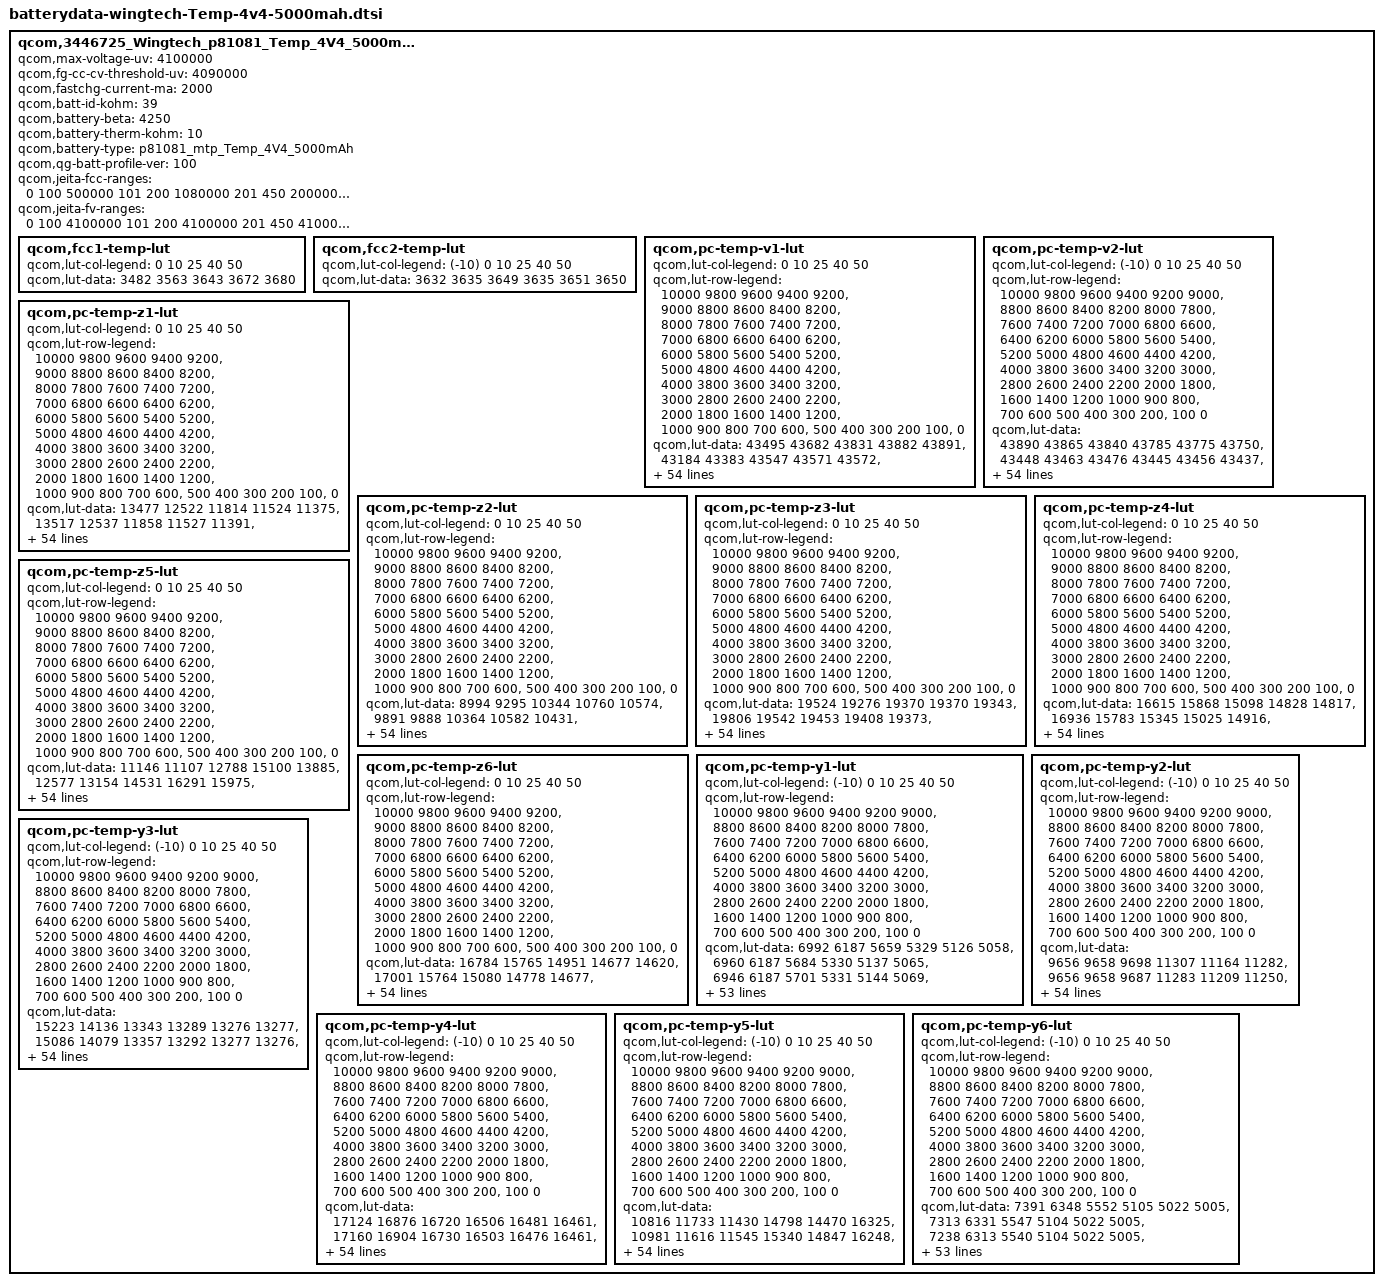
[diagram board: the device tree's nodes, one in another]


qcom,3446725_Wingtech_p81081_Temp_4V4_5000mAh {
	/* 3446725_Wingtech_k81822_Jiade_3600mAh_averaged_MasterSlave_May16th2018 */
	qcom,max-voltage-uv = <4100000>;
	qcom,fg-cc-cv-threshold-uv = <4090000>;
	qcom,fastchg-current-ma = <2000>;
	qcom,batt-id-kohm = <39>;
	qcom,battery-beta = <4250>;
	qcom,battery-therm-kohm = <10>;
	qcom,battery-type = "p81081_mtp_Temp_4V4_5000mAh";
	qcom,qg-batt-profile-ver = <100>;
	/*bug 356255 zhaolinquan.wt 20170522 0-45 degree C charging, other temperatur don't charging*/
	/* COLD = 0 DegC, HOT = 45 DegC */
	//qcom,jeita-hard-thresholds = <0x6894 0xb14>;//bug 357121 zhaolinquan.wt 20170524 0 and 45 degree C stop charging is not accurate
	//+bug 356474 zhaolinquan.wt 20170524 0-45 degree C setting charging current by batt SPEC
	qcom,jeita-fcc-ranges = <0   100  500000
				101  200  1080000
				201  450  2000000
				451  580  1000000>;
	qcom,jeita-fv-ranges = <0   100  4100000
				101 200  4100000
				201 450  4100000
				451 580  4100000>;
	//+bug 356474 zhaolinquan.wt 20170524 0-45 degree C setting charging current by batt SPEC
	qcom,fcc1-temp-lut {
		qcom,lut-col-legend = <0 10 25 40 50>;
		qcom,lut-data = <3482 3563 3643 3672 3680>;
	};

	qcom,fcc2-temp-lut {
		qcom,lut-col-legend = <(-10) 0 10 25 40 50>;
		qcom,lut-data = <3632 3635 3649 3635 3651 3650>;
	};

	qcom,pc-temp-v1-lut {
		qcom,lut-col-legend = <0 10 25 40 50>;
		qcom,lut-row-legend = <10000 9800 9600 9400 9200>,
			<9000 8800 8600 8400 8200>,
			<8000 7800 7600 7400 7200>,
			<7000 6800 6600 6400 6200>,
			<6000 5800 5600 5400 5200>,
			<5000 4800 4600 4400 4200>,
			<4000 3800 3600 3400 3200>,
			<3000 2800 2600 2400 2200>,
			<2000 1800 1600 1400 1200>,
			<1000 900 800 700 600>,
			<500 400 300 200 100>,
			<0>;
		qcom,lut-data = <43495 43682 43831 43882 43891>,
			<43184 43383 43547 43571 43572>,
			<42923 43108 43282 43309 43309>,
			<42685 42857 43027 43064 43062>,
			<42451 42623 42780 42822 42821>,
			<42225 42390 42541 42584 42586>,
			<42005 42159 42304 42349 42355>,
			<41790 41935 42068 42113 42120>,
			<41583 41715 41837 41881 41888>,
			<41387 41503 41611 41653 41661>,
			<41215 41307 41390 41429 41438>,
			<41035 41135 41186 41210 41219>,
			<40804 40952 41001 40994 41003>,
			<40530 40713 40806 40786 40793>,
			<40286 40440 40565 40585 40591>,
			<40082 40218 40321 40391 40397>,
			<39902 40041 40136 40207 40211>,
			<39752 39886 39992 40031 40034>,
			<39627 39749 39850 39862 39863>,
			<39508 39625 39707 39708 39706>,
			<39390 39495 39556 39560 39557>,
			<39275 39356 39360 39375 39378>,
			<39155 39206 39112 39122 39138>,
			<39028 39014 38904 38898 38917>,
			<38907 38791 38746 38755 38769>,
			<38798 38628 38618 38642 38650>,
			<38699 38518 38523 38537 38539>,
			<38609 38433 38450 38440 38435>,
			<38528 38373 38380 38352 38342>,
			<38454 38327 38308 38272 38256>,
			<38385 38285 38241 38200 38180>,
			<38320 38243 38183 38134 38111>,
			<38268 38206 38131 38075 38051>,
			<38230 38174 38086 38021 37995>,
			<38197 38148 38048 37974 37945>,
			<38161 38120 38012 37930 37897>,
			<38124 38093 37974 37882 37840>,
			<38081 38060 37934 37833 37777>,
			<38028 38010 37879 37770 37705>,
			<37962 37931 37795 37687 37620>,
			<37881 37836 37694 37589 37523>,
			<37768 37721 37584 37480 37414>,
			<37637 37586 37457 37356 37287>,
			<37484 37427 37303 37203 37134>,
			<37336 37273 37157 37059 36995>,
			<37226 37167 37057 36966 36906>,
			<37189 37132 37036 36940 36878>,
			<37161 37106 37014 36921 36862>,
			<37136 37084 36998 36905 36844>,
			<37094 37043 36956 36849 36779>,
			<36908 36828 36722 36585 36493>,
			<36477 36390 36292 36146 36050>,
			<35914 35817 35721 35569 35471>,
			<35148 35032 34938 34778 34677>,
			<33939 33797 33721 33544 33438>,
			<30000 30000 30000 30000 30000>;
	};

	qcom,pc-temp-v2-lut {
		qcom,lut-col-legend = <(-10) 0 10 25 40 50>;
		qcom,lut-row-legend = <10000 9800 9600 9400 9200 9000>,
			<8800 8600 8400 8200 8000 7800>,
			<7600 7400 7200 7000 6800 6600>,
			<6400 6200 6000 5800 5600 5400>,
			<5200 5000 4800 4600 4400 4200>,
			<4000 3800 3600 3400 3200 3000>,
			<2800 2600 2400 2200 2000 1800>,
			<1600 1400 1200 1000 900 800>,
			<700 600 500 400 300 200>,
			<100 0>;
		qcom,lut-data = <43890 43865 43840 43785 43775 43750>,
			<43448 43463 43476 43445 43456 43437>,
			<43055 43099 43145 43136 43162 43145>,
			<42718 42781 42853 42862 42894 42881>,
			<42429 42501 42595 42620 42652 42640>,
			<42161 42239 42348 42386 42416 42404>,
			<41898 41985 42099 42150 42181 42169>,
			<41654 41744 41861 41918 41949 41937>,
			<41442 41511 41640 41690 41720 41709>,
			<41255 41283 41432 41466 41494 41483>,
			<41080 41092 41230 41248 41273 41261>,
			<40931 40965 41039 41037 41057 41045>,
			<40771 40839 40845 40829 40846 40834>,
			<40492 40595 40620 40618 40642 40630>,
			<40054 40187 40369 40402 40441 40431>,
			<39709 39858 40146 40203 40249 40240>,
			<39503 39661 39964 40028 40067 40056>,
			<39333 39492 39790 39864 39892 39880>,
			<39162 39307 39600 39708 39727 39715>,
			<38997 39120 39402 39561 39571 39560>,
			<38849 38944 39199 39387 39393 39384>,
			<38715 38778 38980 39151 39173 39169>,
			<38595 38629 38780 38912 38957 38957>,
			<38488 38503 38628 38737 38774 38775>,
			<38391 38392 38501 38591 38610 38610>,
			<38304 38299 38387 38466 38477 38475>,
			<38227 38220 38285 38359 38368 38367>,
			<38157 38152 38193 38263 38273 38270>,
			<38091 38089 38114 38174 38184 38178>,
			<38029 38031 38044 38093 38104 38094>,
			<37969 37979 37982 38019 38031 38020>,
			<37910 37932 37928 37950 37962 37953>,
			<37854 37887 37878 37888 37899 37891>,
			<37798 37841 37832 37832 37842 37833>,
			<37744 37796 37790 37782 37787 37775>,
			<37688 37749 37745 37729 37715 37693>,
			<37630 37699 37699 37673 37622 37575>,
			<37569 37644 37648 37614 37529 37464>,
			<37499 37580 37585 37546 37448 37378>,
			<37424 37507 37513 37472 37368 37298>,
			<37350 37426 37429 37391 37288 37215>,
			<37277 37330 37327 37298 37205 37128>,
			<37203 37218 37209 37191 37101 37023>,
			<37129 37089 37074 37064 36971 36898>,
			<37050 36971 36937 36913 36835 36773>,
			<36960 36881 36848 36855 36795 36738>,
			<36908 36846 36815 36844 36782 36723>,
			<36843 36810 36785 36824 36765 36708>,
			<36759 36764 36737 36800 36733 36673>,
			<36616 36680 36645 36734 36630 36542>,
			<36364 36485 36413 36486 36312 36169>,
			<35953 36064 35943 36018 35802 35640>,
			<35361 35447 35297 35409 35139 34952>,
			<34484 34574 34384 34584 34214 33971>,
			<32961 33140 33067 33299 32857 32625>,
			<28877 29996 27778 28495 27598 27650>;
	};

	qcom,pc-temp-z1-lut {
		qcom,lut-col-legend = <0 10 25 40 50>;
		qcom,lut-row-legend = <10000 9800 9600 9400 9200>,
			<9000 8800 8600 8400 8200>,
			<8000 7800 7600 7400 7200>,
			<7000 6800 6600 6400 6200>,
			<6000 5800 5600 5400 5200>,
			<5000 4800 4600 4400 4200>,
			<4000 3800 3600 3400 3200>,
			<3000 2800 2600 2400 2200>,
			<2000 1800 1600 1400 1200>,
			<1000 900 800 700 600>,
			<500 400 300 200 100>,
			<0>;
		qcom,lut-data = <13477 12522 11814 11524 11375>,
			<13517 12537 11858 11527 11391>,
			<13522 12543 11845 11520 11378>,
			<13529 12533 11830 11509 11367>,
			<13530 12516 11820 11499 11359>,
			<13526 12510 11810 11488 11352>,
			<13519 12509 11802 11479 11347>,
			<13504 12510 11791 11474 11343>,
			<13483 12511 11784 11470 11340>,
			<13471 12513 11786 11468 11338>,
			<13470 12510 11791 11468 11337>,
			<13467 12496 11797 11467 11336>,
			<13440 12479 11806 11467 11337>,
			<13384 12462 11810 11467 11337>,
			<13345 12443 11801 11468 11338>,
			<13320 12439 11787 11471 11340>,
			<13301 12445 11787 11472 11341>,
			<13302 12453 11797 11472 11343>,
			<13317 12461 11804 11472 11345>,
			<13331 12468 11807 11475 11348>,
			<13343 12478 11810 11479 11350>,
			<13353 12491 11811 11481 11352>,
			<13362 12503 11810 11481 11353>,
			<13385 12509 11810 11482 11354>,
			<13403 12514 11812 11485 11357>,
			<13404 12515 11816 11490 11361>,
			<13399 12516 11821 11493 11365>,
			<13393 12517 11828 11496 11369>,
			<13388 12515 11833 11499 11373>,
			<13385 12511 11837 11506 11377>,
			<13389 12511 11839 11515 11382>,
			<13406 12517 11838 11518 11386>,
			<13415 12526 11836 11520 11390>,
			<13420 12535 11836 11522 11394>,
			<13429 12547 11846 11526 11399>,
			<13438 12558 11855 11532 11403>,
			<13455 12570 11855 11539 11408>,
			<13467 12580 11854 11547 11412>,
			<13466 12583 11855 11552 11417>,
			<13463 12580 11864 11554 11422>,
			<13466 12580 11872 11556 11427>,
			<13494 12588 11874 11559 11431>,
			<13506 12594 11875 11561 11435>,
			<13495 12589 11870 11562 11438>,
			<13509 12590 11874 11564 11442>,
			<13437 12582 11878 11570 11440>,
			<13451 12588 11879 11571 11441>,
			<13451 12587 11877 11576 11446>,
			<13429 12576 11878 11573 11450>,
			<13467 12595 11882 11572 11453>,
			<13480 12605 11880 11580 11458>,
			<13482 12626 11895 11583 11462>,
			<13511 12671 11913 11598 11471>,
			<13557 12687 11934 11619 11483>,
			<13557 12687 11934 11619 11483>,
			<13557 12687 11934 11619 11483>;
	};

	qcom,pc-temp-z2-lut {
		qcom,lut-col-legend = <0 10 25 40 50>;
		qcom,lut-row-legend = <10000 9800 9600 9400 9200>,
			<9000 8800 8600 8400 8200>,
			<8000 7800 7600 7400 7200>,
			<7000 6800 6600 6400 6200>,
			<6000 5800 5600 5400 5200>,
			<5000 4800 4600 4400 4200>,
			<4000 3800 3600 3400 3200>,
			<3000 2800 2600 2400 2200>,
			<2000 1800 1600 1400 1200>,
			<1000 900 800 700 600>,
			<500 400 300 200 100>,
			<0>;
		qcom,lut-data = <8994 9295 10344 10760 10574>,
			<9891 9888 10364 10582 10431>,
			<10002 10182 10407 10567 10479>,
			<10056 10172 10420 10525 10520>,
			<10091 10146 10400 10485 10520>,
			<10120 10126 10355 10435 10459>,
			<10134 10107 10327 10411 10417>,
			<10132 10094 10307 10417 10432>,
			<10125 10085 10297 10427 10455>,
			<10118 10079 10310 10439 10443>,
			<10110 10081 10336 10453 10372>,
			<10098 10111 10357 10462 10332>,
			<10069 10136 10377 10467 10352>,
			<10018 10134 10394 10470 10379>,
			<9997 10127 10406 10458 10387>,
			<10054 10128 10417 10429 10386>,
			<10126 10161 10433 10419 10382>,
			<10119 10210 10456 10441 10377>,
			<10033 10268 10475 10462 10373>,
			<9948 10336 10490 10466 10383>,
			<9790 10356 10501 10468 10411>,
			<9580 10333 10493 10474 10433>,
			<9558 10304 10459 10493 10463>,
			<9797 10284 10434 10506 10484>,
			<10007 10263 10422 10482 10494>,
			<10028 10257 10414 10439 10518>,
			<10035 10269 10424 10446 10536>,
			<10032 10283 10458 10531 10545>,
			<9874 10289 10472 10583 10542>,
			<9703 10292 10466 10527 10476>,
			<9695 10296 10458 10446 10373>,
			<9709 10304 10449 10431 10323>,
			<9717 10313 10437 10430 10290>,
			<9601 10300 10435 10432 10277>,
			<9439 10242 10454 10463 10301>,
			<9430 10213 10480 10510 10344>,
			<9482 10241 10501 10551 10394>,
			<9519 10290 10522 10595 10465>,
			<9524 10341 10543 10622 10520>,
			<9526 10403 10567 10642 10560>,
			<9520 10432 10585 10657 10586>,
			<9487 10508 10593 10665 10586>,
			<9451 10573 10599 10670 10577>,
			<9420 10500 10607 10650 10584>,
			<9385 10738 10661 10642 10595>,
			<9361 10799 10727 10645 10601>,
			<9368 10844 10778 10675 10588>,
			<9362 10811 10824 10679 10579>,
			<9355 11060 13704 10785 10655>,
			<9362 10784 11298 10870 10888>,
			<9342 10694 11036 10734 10476>,
			<9327 10519 10992 10588 10381>,
			<9284 10094 11006 10533 10322>,
			<9246 9998 10846 10474 10267>,
			<9246 9998 10846 10474 10267>,
			<9246 9998 10846 10474 10267>;
	};

	qcom,pc-temp-z3-lut {
		qcom,lut-col-legend = <0 10 25 40 50>;
		qcom,lut-row-legend = <10000 9800 9600 9400 9200>,
			<9000 8800 8600 8400 8200>,
			<8000 7800 7600 7400 7200>,
			<7000 6800 6600 6400 6200>,
			<6000 5800 5600 5400 5200>,
			<5000 4800 4600 4400 4200>,
			<4000 3800 3600 3400 3200>,
			<3000 2800 2600 2400 2200>,
			<2000 1800 1600 1400 1200>,
			<1000 900 800 700 600>,
			<500 400 300 200 100>,
			<0>;
		qcom,lut-data = <19524 19276 19370 19370 19343>,
			<19806 19542 19453 19408 19373>,
			<19850 19682 19491 19419 19391>,
			<19871 19695 19509 19424 19404>,
			<19867 19702 19514 19427 19407>,
			<19827 19702 19516 19429 19406>,
			<19787 19697 19516 19430 19405>,
			<19768 19689 19514 19427 19403>,
			<19753 19678 19511 19421 19399>,
			<19743 19663 19503 19414 19393>,
			<19731 19642 19489 19405 19383>,
			<19723 19603 19476 19400 19376>,
			<19730 19576 19462 19397 19374>,
			<19757 19586 19456 19395 19373>,
			<19788 19608 19459 19390 19369>,
			<19833 19613 19465 19382 19364>,
			<19872 19591 19461 19378 19360>,
			<19842 19558 19439 19376 19357>,
			<19679 19508 19426 19375 19355>,
			<19539 19444 19427 19374 19352>,
			<19451 19427 19428 19372 19350>,
			<19367 19479 19434 19373 19349>,
			<19372 19542 19453 19379 19353>,
			<19552 19577 19462 19384 19356>,
			<19705 19607 19456 19375 19349>,
			<19712 19617 19447 19358 19334>,
			<19712 19616 19443 19360 19336>,
			<19707 19613 19440 19386 19374>,
			<19620 19609 19439 19404 19399>,
			<19525 19600 19449 19407 19397>,
			<19513 19590 19460 19408 19392>,
			<19508 19580 19461 19407 19386>,
			<19499 19569 19459 19402 19378>,
			<19414 19532 19456 19397 19370>,
			<19299 19447 19451 19391 19361>,
			<19273 19400 19445 19385 19354>,
			<19271 19340 19442 19381 19354>,
			<19270 19271 19439 19378 19354>,
			<19269 19262 19437 19376 19354>,
			<19269 19261 19435 19374 19352>,
			<19269 19261 19432 19372 19350>,
			<19270 19261 19429 19368 19349>,
			<19271 19260 19425 19364 19348>,
			<19272 19260 19420 19361 19351>,
			<19274 19259 19408 19359 19351>,
			<19275 19259 19395 19349 19337>,
			<19274 19259 19349 19342 19334>,
			<19275 19259 19350 19346 19325>,
			<19275 19259 19296 19329 19320>,
			<19275 19259 19298 19326 19307>,
			<19276 19259 19325 19340 19351>,
			<19277 19260 19326 19354 19357>,
			<19281 19262 19311 19352 19356>,
			<19284 19262 19314 19358 19359>,
			<19284 19262 19314 19358 19359>,
			<19284 19262 19314 19358 19359>;
	};

	qcom,pc-temp-z4-lut {
		qcom,lut-col-legend = <0 10 25 40 50>;
		qcom,lut-row-legend = <10000 9800 9600 9400 9200>,
			<9000 8800 8600 8400 8200>,
			<8000 7800 7600 7400 7200>,
			<7000 6800 6600 6400 6200>,
			<6000 5800 5600 5400 5200>,
			<5000 4800 4600 4400 4200>,
			<4000 3800 3600 3400 3200>,
			<3000 2800 2600 2400 2200>,
			<2000 1800 1600 1400 1200>,
			<1000 900 800 700 600>,
			<500 400 300 200 100>,
			<0>;
		qcom,lut-data = <16615 15868 15098 14828 14817>,
			<16936 15783 15345 15025 14916>,
			<16705 15668 15207 14989 14909>,
			<16311 15496 15052 14912 14860>,
			<16058 15292 14968 14862 14824>,
			<15880 15160 14901 14826 14795>,
			<15735 15070 14849 14797 14773>,
			<15617 15003 14805 14773 14756>,
			<15517 14950 14775 14754 14743>,
			<15431 14909 14758 14743 14737>,
			<15357 14888 14746 14736 14734>,
			<15290 14879 14736 14728 14730>,
			<15230 14869 14728 14717 14721>,
			<15175 14839 14722 14707 14711>,
			<15109 14796 14718 14701 14703>,
			<14991 14784 14714 14696 14697>,
			<14886 14786 14709 14690 14690>,
			<14903 14791 14702 14681 14683>,
			<15045 14818 14694 14673 14676>,
			<15159 14873 14684 14666 14670>,
			<15231 14887 14675 14660 14665>,
			<15310 14814 14689 14668 14669>,
			<15299 14743 14751 14744 14737>,
			<15079 14758 14798 14811 14802>,
			<14885 14806 14824 14826 14818>,
			<14861 14826 14840 14834 14827>,
			<14852 14825 14835 14827 14820>,
			<14850 14822 14809 14781 14761>,
			<14940 14813 14781 14739 14712>,
			<15041 14790 14751 14716 14699>,
			<15049 14773 14724 14699 14691>,
			<15042 14761 14709 14688 14684>,
			<15035 14753 14697 14679 14678>,
			<15107 14772 14690 14675 14675>,
			<15212 14848 14685 14673 14673>,
			<15226 14887 14681 14671 14671>,
			<15211 14939 14679 14672 14672>,
			<15195 15003 14678 14675 14676>,
			<15182 15010 14679 14678 14680>,
			<15169 15008 14686 14686 14686>,
			<15158 15006 14693 14692 14690>,
			<15149 15002 14690 14689 14686>,
			<15136 14995 14686 14684 14680>,
			<15114 14986 14689 14689 14682>,
			<15017 14941 14686 14686 14679>,
			<14986 14906 14672 14675 14670>,
			<14983 14901 14710 14670 14664>,
			<14976 14894 14699 14649 14654>,
			<14971 14890 14750 14654 14640>,
			<14964 14884 14747 14658 14657>,
			<14970 14896 14735 14670 14643>,
			<14993 14909 14741 14661 14645>,
			<15009 14918 14763 14668 14650>,
			<15034 14932 14766 14667 14653>,
			<15034 14932 14766 14667 14653>,
			<15034 14932 14766 14667 14653>;
	};

	qcom,pc-temp-z5-lut {
		qcom,lut-col-legend = <0 10 25 40 50>;
		qcom,lut-row-legend = <10000 9800 9600 9400 9200>,
			<9000 8800 8600 8400 8200>,
			<8000 7800 7600 7400 7200>,
			<7000 6800 6600 6400 6200>,
			<6000 5800 5600 5400 5200>,
			<5000 4800 4600 4400 4200>,
			<4000 3800 3600 3400 3200>,
			<3000 2800 2600 2400 2200>,
			<2000 1800 1600 1400 1200>,
			<1000 900 800 700 600>,
			<500 400 300 200 100>,
			<0>;
		qcom,lut-data = <11146 11107 12788 15100 13885>,
			<12577 13154 14531 16291 15975>,
			<13077 14469 15660 16881 16955>,
			<13363 15007 16570 17275 18183>,
			<13454 15360 17327 17715 18793>,
			<13489 15709 17994 18197 19047>,
			<13517 16075 18911 18754 19341>,
			<13560 16342 20311 19647 20091>,
			<13607 16493 21260 20432 20911>,
			<13618 16598 21505 20492 20865>,
			<13593 16524 21649 20388 20070>,
			<13591 15698 21581 20370 19644>,
			<13728 15004 21094 21265 20388>,
			<14132 16548 20786 22246 21377>,
			<14772 19885 23415 22195 21593>,
			<16878 20832 27283 21866 21658>,
			<19132 19467 27027 21849 21813>,
			<18656 17585 23022 23368 22750>,
			<15049 15746 20779 25243 24072>,
			<12334 13815 21712 26639 25402>,
			<11600 13378 23905 28275 26835>,
			<11088 15963 29792 29527 27200>,
			<11297 20557 43433 30813 26626>,
			<13801 29808 49570 31528 25555>,
			<16419 44816 40649 26875 21966>,
			<17458 50238 28806 18748 16481>,
			<18152 46846 24272 17313 15686>,
			<18693 41787 21498 18918 19151>,
			<18401 37643 20749 20943 22685>,
			<17826 33560 22520 23072 24737>,
			<17741 30258 25169 25539 26354>,
			<17618 27822 27722 28303 27457>,
			<17371 25692 30774 31620 28388>,
			<14943 22925 32205 33863 28802>,
			<11669 19052 32705 35191 28357>,
			<11019 16906 33043 35987 27790>,
			<11017 14338 33295 35569 28131>,
			<11016 11569 33481 33779 29188>,
			<11026 11235 33407 31757 29512>,
			<11053 11290 32058 29123 26940>,
			<11081 11319 30312 26392 23950>,
			<11109 11296 28906 24306 22847>,
			<11147 11277 27512 22584 22126>,
			<11199 11307 25421 21182 22358>,
			<11487 11501 24482 21305 22158>,
			<11552 11538 23985 19942 19336>,
			<11527 11515 15829 19095 19098>,
			<11526 11519 15647 21449 18373>,
			<11522 11484 12968 17852 18989>,
			<11520 11519 13057 17520 15592>,
			<11575 11541 13795 16999 23640>,
			<11516 11484 13492 18859 23181>,
			<11433 11397 12723 17623 21257>,
			<11311 11311 12660 17907 20288>,
			<11311 11311 12660 17907 20288>,
			<11311 11311 12660 17907 20288>;
	};

	qcom,pc-temp-z6-lut {
		qcom,lut-col-legend = <0 10 25 40 50>;
		qcom,lut-row-legend = <10000 9800 9600 9400 9200>,
			<9000 8800 8600 8400 8200>,
			<8000 7800 7600 7400 7200>,
			<7000 6800 6600 6400 6200>,
			<6000 5800 5600 5400 5200>,
			<5000 4800 4600 4400 4200>,
			<4000 3800 3600 3400 3200>,
			<3000 2800 2600 2400 2200>,
			<2000 1800 1600 1400 1200>,
			<1000 900 800 700 600>,
			<500 400 300 200 100>,
			<0>;
		qcom,lut-data = <16784 15765 14951 14677 14620>,
			<17001 15764 15080 14778 14677>,
			<16856 15750 15025 14763 14678>,
			<16600 15668 14959 14730 14664>,
			<16414 15520 14916 14707 14651>,
			<16264 15421 14879 14691 14637>,
			<16140 15353 14849 14676 14625>,
			<16045 15298 14822 14662 14616>,
			<15966 15250 14802 14650 14608>,
			<15898 15209 14787 14640 14600>,
			<15838 15174 14776 14632 14594>,
			<15785 15142 14765 14625 14588>,
			<15738 15115 14754 14619 14582>,
			<15695 15096 14747 14613 14577>,
			<15656 15080 14744 14607 14572>,
			<15620 15067 14741 14601 14566>,
			<15587 15055 14735 14596 14561>,
			<15558 15046 14723 14592 14556>,
			<15530 15040 14717 14588 14553>,
			<15514 15036 14715 14584 14549>,
			<15509 15034 14714 14582 14545>,
			<15505 15036 14723 14586 14548>,
			<15505 15040 14761 14624 14581>,
			<15509 15060 14787 14654 14610>,
			<15512 15102 14796 14654 14610>,
			<15512 15118 14801 14653 14610>,
			<15510 15119 14798 14651 14609>,
			<15508 15118 14788 14646 14604>,
			<15506 15114 14779 14640 14598>,
			<15503 15103 14774 14634 14593>,
			<15501 15094 14769 14628 14587>,
			<15498 15088 14765 14623 14582>,
			<15495 15082 14761 14618 14576>,
			<15489 15076 14758 14614 14571>,
			<15482 15069 14755 14611 14566>,
			<15480 15065 14753 14608 14562>,
			<15479 15063 14754 14608 14562>,
			<15478 15062 14755 14609 14565>,
			<15479 15064 14757 14610 14567>,
			<15482 15071 14763 14614 14570>,
			<15484 15077 14767 14617 14571>,
			<15487 15080 14767 14615 14570>,
			<15488 15083 14766 14611 14568>,
			<15484 15087 14768 14613 14571>,
			<15455 15078 14766 14613 14570>,
			<15443 15069 14757 14604 14560>,
			<15440 15066 14751 14599 14555>,
			<15439 15065 14746 14592 14547>,
			<15437 15065 14744 14585 14539>,
			<15435 15067 14745 14588 14540>,
			<15451 15079 14758 14602 14559>,
			<15471 15093 14764 14608 14565>,
			<15494 15110 14771 14613 14569>,
			<15531 15133 14782 14620 14575>,
			<15531 15133 14782 14620 14575>,
			<15531 15133 14782 14620 14575>;
	};

	qcom,pc-temp-y1-lut {
		qcom,lut-col-legend = <(-10) 0 10 25 40 50>;
		qcom,lut-row-legend = <10000 9800 9600 9400 9200 9000>,
			<8800 8600 8400 8200 8000 7800>,
			<7600 7400 7200 7000 6800 6600>,
			<6400 6200 6000 5800 5600 5400>,
			<5200 5000 4800 4600 4400 4200>,
			<4000 3800 3600 3400 3200 3000>,
			<2800 2600 2400 2200 2000 1800>,
			<1600 1400 1200 1000 900 800>,
			<700 600 500 400 300 200>,
			<100 0>;
		qcom,lut-data = <6992 6187 5659 5329 5126 5058>,
			<6960 6187 5684 5330 5137 5065>,
			<6946 6187 5701 5331 5144 5069>,
			<6942 6188 5710 5331 5148 5070>,
			<6944 6189 5713 5330 5150 5070>,
			<6946 6192 5713 5330 5150 5069>,
			<6958 6196 5704 5330 5147 5065>,
			<6972 6201 5692 5329 5142 5060>,
			<6967 6205 5694 5327 5140 5059>,
			<6954 6215 5705 5322 5139 5058>,
			<6945 6219 5713 5319 5138 5057>,
			<6947 6214 5711 5318 5136 5055>,
			<6952 6208 5707 5318 5135 5052>,
			<6959 6204 5711 5321 5135 5052>,
			<6980 6203 5719 5330 5136 5051>,
			<6989 6203 5724 5335 5136 5051>,
			<6980 6204 5723 5338 5136 5052>,
			<6970 6205 5721 5339 5136 5053>,
			<6966 6212 5720 5341 5136 5053>,
			<6964 6230 5717 5343 5135 5053>,
			<6964 6239 5718 5343 5135 5053>,
			<6979 6237 5726 5338 5137 5053>,
			<6996 6233 5733 5333 5139 5054>,
			<7000 6229 5732 5334 5140 5055>,
			<6999 6223 5727 5339 5140 5056>,
			<6995 6221 5725 5342 5142 5058>,
			<6984 6227 5727 5344 5143 5059>,
			<6974 6235 5729 5345 5145 5060>,
			<6984 6238 5727 5344 5147 5062>,
			<7009 6241 5724 5343 5149 5065>,
			<7014 6243 5722 5342 5151 5068>,
			<6975 6245 5724 5346 5154 5071>,
			<6938 6246 5726 5349 5156 5074>,
			<6950 6240 5728 5350 5159 5076>,
			<6980 6228 5731 5349 5163 5078>,
			<6990 6223 5730 5350 5164 5080>,
			<6978 6226 5725 5351 5165 5082>,
			<6968 6229 5721 5352 5166 5084>,
			<6974 6229 5723 5351 5167 5086>,
			<6987 6227 5727 5350 5168 5087>,
			<6992 6224 5730 5350 5169 5089>,
			<6997 6217 5732 5354 5169 5091>,
			<6977 6218 5728 5355 5172 5092>,
			<6924 6230 5721 5353 5177 5093>,
			<6978 6235 5728 5364 5177 5095>,
			<7006 6236 5749 5358 5181 5103>,
			<7002 6261 5730 5355 5179 5101>,
			<7007 6257 5737 5359 5183 5101>,
			<7005 6279 5732 5360 5182 5100>,
			<7018 6269 5733 5370 5183 5099>,
			<7046 6287 5745 5364 5183 5104>,
			<7019 6297 5757 5362 5186 5109>,
			<7090 6300 5777 5383 5197 5116>,
			<7172 6329 5803 5401 5206 5125>,
			<7172 6329 5803 5401 5206 5125>,
			<7172 6329 5803 5401 5206 5125>;
	};

	qcom,pc-temp-y2-lut {
		qcom,lut-col-legend = <(-10) 0 10 25 40 50>;
		qcom,lut-row-legend = <10000 9800 9600 9400 9200 9000>,
			<8800 8600 8400 8200 8000 7800>,
			<7600 7400 7200 7000 6800 6600>,
			<6400 6200 6000 5800 5600 5400>,
			<5200 5000 4800 4600 4400 4200>,
			<4000 3800 3600 3400 3200 3000>,
			<2800 2600 2400 2200 2000 1800>,
			<1600 1400 1200 1000 900 800>,
			<700 600 500 400 300 200>,
			<100 0>;
		qcom,lut-data = <9656 9658 9698 11307 11164 11282>,
			<9656 9658 9687 11283 11209 11250>,
			<9656 9658 9686 11257 11243 11210>,
			<9656 9659 9693 11233 11265 11169>,
			<9656 9659 9705 11212 11276 11136>,
			<9656 9659 9721 11197 11278 11118>,
			<9656 9660 9739 11187 11260 11111>,
			<9656 9660 9768 11178 11228 11107>,
			<9657 9661 9917 11154 11192 11096>,
			<9657 9661 10353 11102 11144 11079>,
			<9657 9661 10608 11057 11107 11069>,
			<9657 9662 10656 11026 11076 11038>,
			<9657 9662 10686 11004 11052 11005>,
			<9657 9662 10718 11008 11044 11004>,
			<9657 9662 10747 11032 11041 11007>,
			<9657 9661 10776 11046 11043 11005>,
			<9657 9661 10810 11057 11054 10995>,
			<9657 9661 10835 11074 11074 10987>,
			<9657 9661 10840 11105 11123 11027>,
			<9657 9661 10841 11165 11205 11139>,
			<9657 9661 10815 11189 11231 11194>,
			<9657 9661 10476 11172 11212 11190>,
			<9657 9661 10110 11154 11195 11178>,
			<9657 9661 9986 11158 11208 11181>,
			<9657 9661 9898 11180 11239 11192>,
			<9657 9660 9847 11204 11251 11206>,
			<9657 9660 9814 11239 11243 11227>,
			<9657 9660 9792 11269 11238 11244>,
			<9657 9659 9780 11284 11279 11268>,
			<9657 9659 9772 11296 11347 11307>,
			<9657 9659 9761 11300 11364 11320>,
			<9657 9659 9749 11301 11351 11323>,
			<9657 9658 9736 11302 11339 11325>,
			<9657 9658 9722 11299 11339 11308>,
			<9657 9658 9709 11294 11342 11281>,
			<9657 9658 9700 11284 11340 11274>,
			<9657 9657 9694 11251 11323 11263>,
			<9657 9657 9689 11218 11316 11259>,
			<9657 9657 9685 11202 11325 11265>,
			<9656 9657 9681 11184 11333 11271>,
			<9656 9656 9678 11144 11330 11269>,
			<9656 9656 9675 11012 11315 11248>,
			<9656 9656 9671 10970 11307 11251>,
			<9655 9655 9668 10997 11297 11259>,
			<9655 9655 9666 10866 11260 11204>,
			<9655 9655 9664 10488 11235 11116>,
			<9655 9655 9663 10894 11192 11097>,
			<9655 9655 9661 10540 11198 11039>,
			<9654 9655 9660 10880 11169 11050>,
			<9654 9654 9659 10847 11152 11030>,
			<9654 9654 9658 10422 11093 10976>,
			<9653 9654 9657 10326 11045 10908>,
			<9653 9653 9656 10602 10993 10849>,
			<9652 9653 9654 10531 10857 10725>,
			<9652 9653 9654 10531 10857 10725>,
			<9652 9653 9654 10531 10857 10725>;
	};

	qcom,pc-temp-y3-lut {
		qcom,lut-col-legend = <(-10) 0 10 25 40 50>;
		qcom,lut-row-legend = <10000 9800 9600 9400 9200 9000>,
			<8800 8600 8400 8200 8000 7800>,
			<7600 7400 7200 7000 6800 6600>,
			<6400 6200 6000 5800 5600 5400>,
			<5200 5000 4800 4600 4400 4200>,
			<4000 3800 3600 3400 3200 3000>,
			<2800 2600 2400 2200 2000 1800>,
			<1600 1400 1200 1000 900 800>,
			<700 600 500 400 300 200>,
			<100 0>;
		qcom,lut-data = <15223 14136 13343 13289 13276 13277>,
			<15086 14079 13357 13292 13277 13276>,
			<14956 14024 13367 13294 13278 13276>,
			<14834 13972 13374 13295 13279 13276>,
			<14723 13927 13377 13296 13280 13276>,
			<14625 13891 13378 13296 13280 13277>,
			<14542 13866 13374 13295 13281 13277>,
			<14467 13843 13369 13294 13282 13278>,
			<14385 13805 13372 13294 13282 13279>,
			<14294 13746 13385 13294 13281 13279>,
			<14250 13718 13391 13296 13280 13279>,
			<14245 13725 13390 13301 13284 13281>,
			<14242 13733 13388 13308 13288 13283>,
			<14216 13720 13386 13309 13288 13283>,
			<14145 13667 13384 13308 13288 13284>,
			<14109 13637 13381 13308 13288 13284>,
			<14107 13632 13378 13311 13290 13284>,
			<14106 13629 13375 13314 13294 13284>,
			<14105 13623 13370 13315 13295 13286>,
			<14103 13613 13362 13315 13295 13288>,
			<14101 13609 13352 13314 13295 13289>,
			<14102 13610 13332 13309 13292 13287>,
			<14103 13613 13318 13303 13288 13284>,
			<14107 13617 13317 13301 13285 13281>,
			<14115 13625 13318 13298 13282 13278>,
			<14127 13636 13315 13297 13281 13277>,
			<14149 13653 13292 13297 13280 13278>,
			<14176 13675 13273 13296 13280 13278>,
			<14202 13696 13273 13295 13281 13277>,
			<14229 13719 13275 13293 13283 13276>,
			<14257 13746 13277 13292 13283 13276>,
			<14286 13781 13280 13293 13282 13277>,
			<14317 13818 13285 13294 13281 13278>,
			<14351 13856 13293 13295 13282 13279>,
			<14387 13897 13305 13297 13284 13280>,
			<14428 13941 13317 13298 13284 13280>,
			<14477 13990 13329 13295 13282 13277>,
			<14528 14043 13341 13293 13281 13276>,
			<14574 14101 13354 13292 13280 13276>,
			<14619 14163 13367 13292 13280 13276>,
			<14671 14228 13384 13291 13281 13276>,
			<14733 14295 13404 13290 13284 13277>,
			<14800 14372 13433 13290 13284 13278>,
			<14874 14459 13468 13294 13284 13280>,
			<14960 14536 13495 13290 13277 13277>,
			<14967 14575 13534 13289 13282 13279>,
			<15050 14651 13576 13300 13285 13281>,
			<15157 14749 13633 13298 13289 13287>,
			<15282 14838 13696 13309 13295 13291>,
			<15402 14941 13770 13314 13294 13291>,
			<15551 15040 13835 13307 13290 13287>,
			<15759 15142 13937 13309 13292 13286>,
			<16044 15331 14174 13322 13295 13291>,
			<16731 15540 14458 13336 13301 13295>,
			<16731 15540 14458 13336 13301 13295>,
			<16731 15540 14458 13336 13301 13295>;
	};

	qcom,pc-temp-y4-lut {
		qcom,lut-col-legend = <(-10) 0 10 25 40 50>;
		qcom,lut-row-legend = <10000 9800 9600 9400 9200 9000>,
			<8800 8600 8400 8200 8000 7800>,
			<7600 7400 7200 7000 6800 6600>,
			<6400 6200 6000 5800 5600 5400>,
			<5200 5000 4800 4600 4400 4200>,
			<4000 3800 3600 3400 3200 3000>,
			<2800 2600 2400 2200 2000 1800>,
			<1600 1400 1200 1000 900 800>,
			<700 600 500 400 300 200>,
			<100 0>;
		qcom,lut-data = <17124 16876 16720 16506 16481 16461>,
			<17160 16904 16730 16503 16476 16461>,
			<17213 16968 16748 16502 16472 16462>,
			<17270 17044 16770 16502 16469 16462>,
			<17318 17106 16787 16503 16468 16462>,
			<17341 17131 16793 16504 16467 16463>,
			<17346 17131 16793 16509 16468 16463>,
			<17350 17132 16792 16516 16470 16464>,
			<17389 17146 16783 16522 16474 16465>,
			<17526 17214 16754 16529 16481 16467>,
			<17598 17290 16741 16532 16485 16470>,
			<17585 17380 16790 16533 16486 16473>,
			<17554 17454 16848 16534 16486 16476>,
			<17444 17393 16850 16538 16490 16480>,
			<17162 17137 16839 16553 16500 16485>,
			<17011 16997 16835 16572 16511 16492>,
			<16994 16982 16846 16595 16519 16501>,
			<16981 16971 16857 16624 16529 16511>,
			<16956 16942 16844 16661 16552 16528>,
			<16920 16890 16799 16707 16588 16550>,
			<16894 16840 16751 16721 16598 16556>,
			<16876 16790 16696 16643 16573 16543>,
			<16866 16750 16650 16546 16538 16524>,
			<16865 16734 16630 16509 16504 16498>,
			<16865 16724 16617 16486 16469 16468>,
			<16865 16720 16617 16479 16461 16460>,
			<16861 16718 16640 16479 16462 16459>,
			<16857 16717 16661 16480 16464 16459>,
			<16857 16718 16662 16484 16467 16462>,
			<16860 16722 16663 16491 16471 16469>,
			<16864 16725 16664 16497 16477 16477>,
			<16877 16726 16669 16500 16489 16486>,
			<16889 16728 16672 16503 16500 16496>,
			<16894 16732 16669 16505 16510 16508>,
			<16897 16741 16663 16508 16519 16518>,
			<16899 16750 16662 16509 16515 16514>,
			<16901 16761 16667 16509 16489 16481>,
			<16902 16770 16671 16508 16470 16461>,
			<16906 16776 16674 16505 16467 16461>,
			<16912 16781 16676 16501 16466 16463>,
			<16918 16785 16677 16501 16467 16466>,
			<16927 16791 16677 16513 16474 16472>,
			<16942 16791 16674 16520 16477 16473>,
			<16969 16780 16669 16523 16477 16471>,
			<16996 16771 16667 16518 16464 16450>,
			<16968 16765 16665 16527 16469 16464>,
			<16987 16775 16683 16523 16481 16481>,
			<17020 16802 16706 16551 16500 16511>,
			<17051 16843 16743 16565 16534 16546>,
			<17066 16890 16794 16597 16540 16538>,
			<17055 16902 16812 16583 16491 16473>,
			<17046 16859 16789 16573 16483 16473>,
			<17045 16854 16805 16583 16500 16488>,
			<17193 16876 16854 16652 16556 16545>,
			<17193 16876 16854 16652 16556 16545>,
			<17193 16876 16854 16652 16556 16545>;
	};

	qcom,pc-temp-y5-lut {
		qcom,lut-col-legend = <(-10) 0 10 25 40 50>;
		qcom,lut-row-legend = <10000 9800 9600 9400 9200 9000>,
			<8800 8600 8400 8200 8000 7800>,
			<7600 7400 7200 7000 6800 6600>,
			<6400 6200 6000 5800 5600 5400>,
			<5200 5000 4800 4600 4400 4200>,
			<4000 3800 3600 3400 3200 3000>,
			<2800 2600 2400 2200 2000 1800>,
			<1600 1400 1200 1000 900 800>,
			<700 600 500 400 300 200>,
			<100 0>;
		qcom,lut-data = <10816 11733 11430 14798 14470 16325>,
			<10981 11616 11545 15340 14847 16248>,
			<11179 11565 11777 15592 15102 16139>,
			<11374 11566 12042 15627 15253 16023>,
			<11530 11602 12260 15519 15318 15928>,
			<11614 11659 12349 15339 15316 15880>,
			<11632 11827 12355 14717 15206 15869>,
			<11641 12016 12358 13906 14993 15860>,
			<11691 11933 13003 13569 14612 15725>,
			<11845 11478 15427 13374 13924 15258>,
			<12149 11257 16606 13315 13633 14948>,
			<14719 13079 15396 13998 14339 15123>,
			<17796 15398 13967 14867 15162 15404>,
			<17175 15148 14287 14798 15009 15360>,
			<13607 13228 15808 14169 14301 15092>,
			<11859 12300 16726 13865 14017 14797>,
			<11896 12468 16984 13949 14291 14328>,
			<11946 12665 17198 14130 14576 13950>,
			<11939 12669 17651 14535 14556 13969>,
			<11912 12603 18291 15467 14449 14131>,
			<11866 12511 18307 16535 14578 14501>,
			<11719 12334 15547 18029 16743 16450>,
			<11530 12099 12926 19236 18721 18157>,
			<11375 11822 12757 19320 18486 18090>,
			<11230 11499 12726 19032 17723 17800>,
			<11185 11392 12600 18887 17195 17726>,
			<11279 11406 11966 18515 16638 17862>,
			<11376 11419 11458 17982 16293 17974>,
			<11414 11405 11439 17385 16726 17273>,
			<11486 11369 11434 16577 17556 15922>,
			<11488 11368 11421 16230 17654 15606>,
			<11409 11532 11375 16475 16968 15781>,
			<11346 11734 11344 16957 16484 16074>,
			<11387 11852 11507 17739 17373 16916>,
			<11506 11947 11842 18797 18821 18010>,
			<11623 12032 12086 18977 19029 18114>,
			<11760 12109 12297 17794 18589 17510>,
			<11845 12172 12395 16581 18049 16968>,
			<11760 12221 12371 16177 17300 16697>,
			<11569 12257 12332 15891 16590 16462>,
			<11466 12235 12318 15415 16880 16238>,
			<11420 12084 12310 14527 18206 16021>,
			<11383 11924 12349 14390 18294 16722>,
			<11353 11736 12401 15153 17558 17986>,
			<11354 11615 11913 13844 15286 16901>,
			<11483 11458 11935 13260 15814 15209>,
			<11616 11571 11829 15600 15992 15201>,
			<11698 11535 12093 14181 16232 15954>,
			<11988 11601 12241 15680 16680 16032>,
			<12150 11766 12631 15638 16342 16551>,
			<12219 12127 12703 14586 16729 18009>,
			<11837 11851 12236 14960 18321 17274>,
			<11938 11712 12335 17459 19016 19190>,
			<11517 11721 12332 18734 20100 19635>,
			<11517 11721 12332 18734 20100 19635>,
			<11517 11721 12332 18734 20100 19635>;
	};

	qcom,pc-temp-y6-lut {
		qcom,lut-col-legend = <(-10) 0 10 25 40 50>;
		qcom,lut-row-legend = <10000 9800 9600 9400 9200 9000>,
			<8800 8600 8400 8200 8000 7800>,
			<7600 7400 7200 7000 6800 6600>,
			<6400 6200 6000 5800 5600 5400>,
			<5200 5000 4800 4600 4400 4200>,
			<4000 3800 3600 3400 3200 3000>,
			<2800 2600 2400 2200 2000 1800>,
			<1600 1400 1200 1000 900 800>,
			<700 600 500 400 300 200>,
			<100 0>;
		qcom,lut-data = <7391 6348 5552 5105 5022 5005>,
			<7313 6331 5547 5104 5022 5005>,
			<7238 6313 5540 5104 5022 5005>,
			<7167 6294 5532 5103 5022 5005>,
			<7100 6274 5523 5102 5022 5005>,
			<7037 6254 5512 5102 5022 5005>,
			<6975 6231 5498 5101 5022 5005>,
			<6921 6209 5485 5100 5023 5006>,
			<6885 6191 5483 5100 5024 5007>,
			<6859 6173 5482 5101 5024 5007>,
			<6840 6166 5482 5103 5025 5008>,
			<6828 6184 5486 5106 5027 5010>,
			<6816 6207 5490 5109 5030 5012>,
			<6764 6183 5486 5112 5032 5013>,
			<6636 6082 5473 5115 5034 5016>,
			<6570 6026 5468 5119 5037 5018>,
			<6565 6020 5470 5128 5041 5020>,
			<6561 6016 5473 5139 5046 5023>,
			<6553 6005 5467 5151 5054 5029>,
			<6541 5986 5445 5162 5065 5037>,
			<6534 5971 5422 5166 5067 5039>,
			<6530 5959 5391 5140 5058 5034>,
			<6528 5952 5367 5109 5044 5026>,
			<6529 5953 5363 5097 5032 5016>,
			<6535 5958 5361 5090 5020 5005>,
			<6544 5966 5361 5088 5017 5003>,
			<6558 5980 5364 5088 5017 5003>,
			<6576 5998 5370 5089 5018 5003>,
			<6595 6016 5377 5091 5020 5004>,
			<6617 6035 5387 5094 5022 5006>,
			<6641 6058 5397 5097 5025 5008>,
			<6667 6085 5409 5100 5028 5011>,
			<6694 6115 5422 5103 5032 5015>,
			<6721 6145 5436 5107 5036 5020>,
			<6748 6178 5451 5112 5041 5023>,
			<6781 6214 5467 5114 5040 5022>,
			<6822 6255 5485 5114 5031 5012>,
			<6865 6299 5505 5114 5026 5005>,
			<6901 6346 5527 5114 5025 5006>,
			<6936 6395 5551 5114 5025 5006>,
			<6979 6446 5578 5115 5026 5008>,
			<7033 6499 5609 5120 5030 5010>,
			<7091 6558 5645 5126 5032 5012>,
			<7155 6623 5685 5133 5033 5013>,
			<7230 6682 5721 5133 5025 5005>,
			<7237 6713 5762 5136 5031 5012>,
			<7307 6770 5807 5146 5037 5018>,
			<7397 6853 5865 5155 5046 5031>,
			<7505 6935 5932 5171 5059 5044>,
			<7606 7027 6009 5186 5061 5042>,
			<7719 7109 6073 5178 5045 5020>,
			<7889 7181 6152 5185 5044 5021>,
			<8123 7330 6347 5213 5054 5030>,
			<8727 7503 6584 5260 5076 5051>,
			<8727 7503 6584 5260 5076 5051>,
			<8727 7503 6584 5260 5076 5051>;
	};

};
